VERSION ""

NS_ :

BS_:

BU_: Vector__XXX

BO_ 1824 TransducerHeartbeat: 1 Vector__XXX
SG_ Heartbeat : 0|8@1+ (1,0) [0|255] "" Vector__XXX

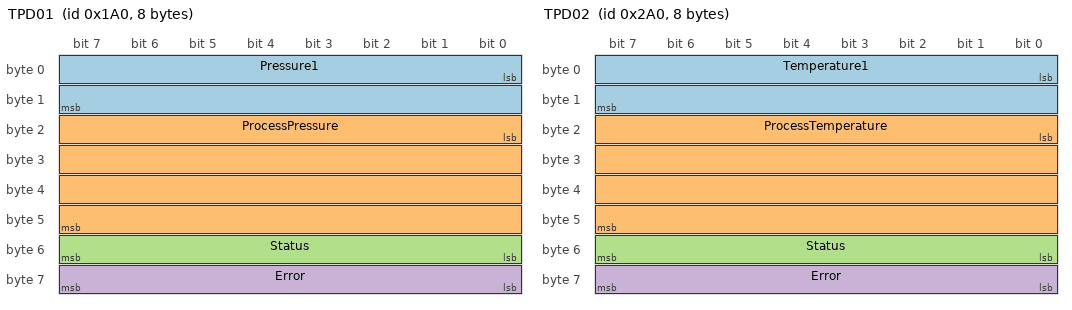
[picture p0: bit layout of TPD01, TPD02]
BO_ 416 TPD01: 8 Vector__XXX
SG_ Pressure1 : 0|16@1+ (0.25,0) [0|5000] "bar" Vector__XXX
SG_ ProcessPressure : 16|32@1+ (1,0) [0|1] "bar" Vector__XXX
SG_ Status : 48|8@1+ (1,0) [0|1] "" Vector__XXX
SG_ Error : 56|8@1+ (1,0) [0|1] "" Vector__XXX

BO_ 672 TPD02: 8 Vector__XXX
SG_ Temperature1 : 0|16@1+ (0.25,0) [0|5000] "C" Vector__XXX
SG_ ProcessTemperature : 16|32@1+ (1,0) [0|4294967295] "C" Vector__XXX
SG_ Status : 48|8@1+ (1,0) [0|1] "" Vector__XXX
SG_ Error : 56|8@1+ (1,0) [0|1] "" Vector__XXX

BA_DEF_  "BusType" STRING ;

BA_DEF_DEF_  "BusType" "CAN";

VAL_ 1824 Heartbeat 0 "bootup" 5 "operational" 127 "preoperational" 255 "stopped";
